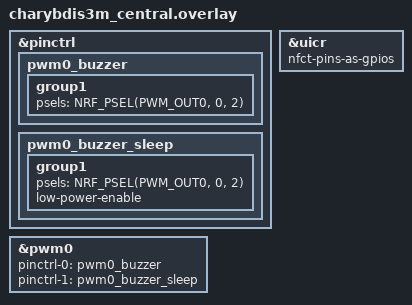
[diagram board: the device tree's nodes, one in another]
/* Dongle only: route PWM0 to the buzzer pin P0.02 (D19). Kept out of the
 * keymap, which every board uses: on the halves this pin belongs to the
 * matrix, and an enabled PWM0 would grab it. */

&pinctrl {
    pwm0_buzzer: pwm0_buzzer {
        group1 {
            psels = <NRF_PSEL(PWM_OUT0, 0, 2)>;
        };
    };

    pwm0_buzzer_sleep: pwm0_buzzer_sleep {
        group1 {
            psels = <NRF_PSEL(PWM_OUT0, 0, 2)>;
            low-power-enable;
        };
    };
};

&pwm0 {
    status = "okay";
    pinctrl-0 = <&pwm0_buzzer>;
    pinctrl-1 = <&pwm0_buzzer_sleep>;
    pinctrl-names = "default", "sleep";
};

/* Dongle only: the vibration motor is on P0.09 (D10). P0.09/P0.10 are the
 * NFC antenna pins by default, so release them as plain GPIOs (written to
 * UICR on first boot, then the chip resets). The motor driver itself is
 * limited to the central by the module's Kconfig. */
&uicr {
    nfct-pins-as-gpios;
};
